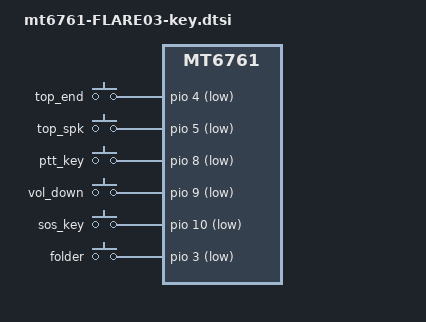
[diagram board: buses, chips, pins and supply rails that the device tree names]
/*
 * This software is contributed or developed by KYOCERA Corporation.
 * (C) 2021 KYOCERA Corporation
 *
 * This program is free software; you can redistribute it and/or modify
 * it under the terms of the GNU General Public License version 2 and
 * only version 2 as published by the Free Software Foundation.
 *
 * This program is distributed in the hope that it will be useful,
 * but WITHOUT ANY WARRANTY; without even the implied warranty of
 * MERCHANTABILITY or FITNESS FOR A PARTICULAR PURPOSE.  See the
 * GNU General Public License for more details.
 */

#include <dt-bindings/pinctrl/mt6761-pinfunc.h>

&pio {
	gpio_keys_default: gpio_keys_default {
		pins_cmd0_dat {
			pinmux = <PINMUX_GPIO4__FUNC_GPIO4>;
			slew-rate = <0>;
			bias-pull-up;
		};
		pins_cmd1_dat {
			pinmux = <PINMUX_GPIO5__FUNC_GPIO5>;
			slew-rate = <0>;
			bias-pull-up;
		};
		pins_cmd2_dat {
			pinmux = <PINMUX_GPIO8__FUNC_GPIO8>;
			slew-rate = <0>;
			bias-pull-up;
		};
		pins_cmd3_dat {
			pinmux = <PINMUX_GPIO9__FUNC_GPIO9>;
			slew-rate = <0>;
			bias-pull-up;
		};
		pins_cmd4_dat {
			pinmux = <PINMUX_GPIO10__FUNC_GPIO10>;
			slew-rate = <0>;
			bias-pull-up;
		};
		pins_cmd5_dat {
			pinmux = <PINMUX_GPIO3__FUNC_GPIO3>;
			slew-rate = <0>;
			bias-disable;
		};
	};
};

&odm {
	gpio_keys {
		compatible = "gpio-keys";
		input-name = "gpio-keys";
		label = "gpio-keys";
		pinctrl-names = "default";
		pinctrl-0 = <&gpio_keys_default>;

		top_end {
			label = "top_end";
			gpios = <&pio 4 1>;
			linux,input-type = <0x1>;
			linux,code = <0x2fc>;	/* KEY_KC_TOP_END[764] */
			debounce-interval = <20>;
			linux,can-disable;
			gpio-key,wakeup;
			on_chattering_num  = <1>;
			off_chattering_num = <0>;
		};

		top_spk {
			label = "top_spk";
			gpios = <&pio 5 1>;
			linux,input-type = <0x1>;
			linux,code = <0x2fd>;	/* KEY_KC_TOP_SPK[765] */
			debounce-interval = <20>;
			linux,can-disable;
			gpio-key,wakeup;
			on_chattering_num  = <1>;
			off_chattering_num = <0>;
		};

		ptt_key {
			label = "ptt_key";
			gpios = <&pio 8 1>;
			linux,input-type = <0x1>;
			linux,code = <0x2fe>;	/* KEY_KC_PTT[766] */
			debounce-interval = <20>;
			linux,can-disable;
			gpio-key,wakeup;
			on_chattering_num  = <1>;
			off_chattering_num = <0>;
		};

		vol_down {
			label = "vol_down";
			gpios = <&pio 9 1>;
			linux,input-type = <0x1>;
			linux,code = <114>;	/* KEY_VOLUMEDOWN */
			debounce-interval = <20>;
			linux,can-disable;
			gpio-key,wakeup;
			on_chattering_num  = <1>;
			off_chattering_num = <0>;
		};

		sos_key {
			label = "sos_key";
			gpios = <&pio 10 1>;
			linux,input-type = <0x1>;
			linux,code = <0x2fb>;	/* KEY_KC_SOS[763] */
			debounce-interval = <20>;
			linux,can-disable;
			gpio-key,wakeup;
			on_chattering_num  = <1>;
			off_chattering_num = <0>;
		};

		folder {
			label = "folder";
			gpios = <&pio 3 1>;
			linux,input-type = <5>;
			linux,code = <0x00>;	/* SW_LID */
			debounce-interval = <25>;
			linux,can-disable;
			gpio-key,wakeup;
			on_chattering_num  = <1>;
			off_chattering_num = <1>;
		};
	};
};

